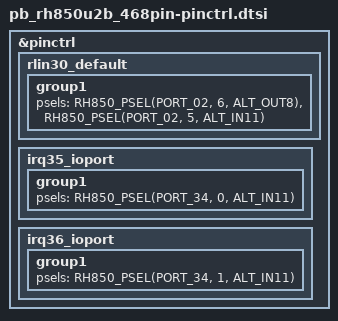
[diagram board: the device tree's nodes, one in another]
/*
 * Copyright (c) 2026 Renesas Electronics Corporation
 * SPDX-License-Identifier: Apache-2.0
 */

#include <dt-bindings/pinctrl/renesas/pinctrl-rh850u2b.h>

&pinctrl {
	rlin30_default: rlin30_default {
		group1 {
			psels = <RH850_PSEL(PORT_02, 6, ALT_OUT8)>,
				<RH850_PSEL(PORT_02, 5, ALT_IN11)>;
		};
	};

	irq35_ioport: irq35_ioport {
		group1 {
			psels = <RH850_PSEL(PORT_34, 0, ALT_IN11)>;
		};
	};

	irq36_ioport: irq36_ioport {
		group1 {
			psels = <RH850_PSEL(PORT_34, 1, ALT_IN11)>;
		};
	};
};
